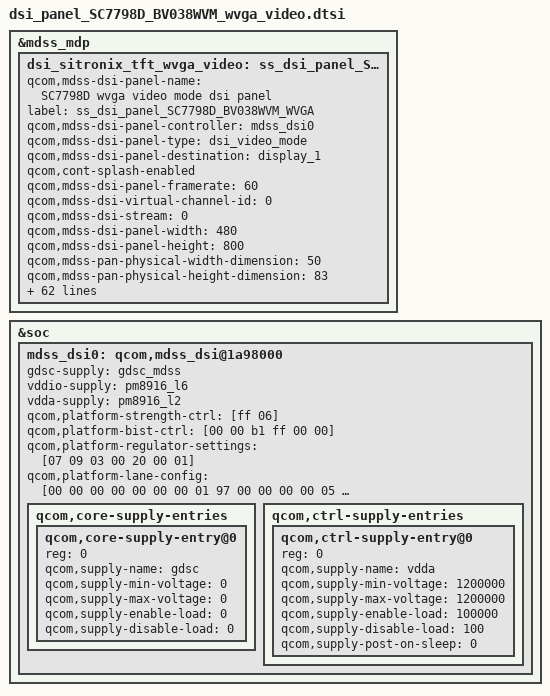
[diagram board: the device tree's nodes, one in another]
/* Copyright (c) 2013-14, Samsung Electronics Corporation. All rights reserved.
 *
 * This program is free software; you can redistribute it and/or modify
 * it under the terms of the GNU General Public License version 2 and
 * only version 2 as published by the Free Software Foundation.
 *
 * This program is distributed in the hope that it will be useful,
 * but WITHOUT ANY WARRANTY; without even the implied warranty of
 * MERCHANTABILITY or FITNESS FOR A PARTICULAR PURPOSE.  See the
 * GNU General Public License for more details.
 */

/*---------------------------------------------------------------------------
 * This file is autogenerated file using gcdb parser. Please do not edit it.
 * Update input XML file to add a new entry or update variable in this file
 * VERSION = "1.0"
 *---------------------------------------------------------------------------*/
&mdss_mdp {
	dsi_sitronix_tft_wvga_video: ss_dsi_panel_SC7798D_BV038WVM_WVGA/*qcom,mdss_dsi_sitronix_wvga_video*/ {
		qcom,mdss-dsi-panel-name = "SC7798D wvga video mode dsi panel";
		label = "ss_dsi_panel_SC7798D_BV038WVM_WVGA";
		qcom,mdss-dsi-panel-controller = <&mdss_dsi0>;
		qcom,mdss-dsi-panel-type = "dsi_video_mode";
		qcom,mdss-dsi-panel-destination = "display_1";
		qcom,cont-splash-enabled;
		qcom,mdss-dsi-panel-framerate = <60>;
		qcom,mdss-dsi-virtual-channel-id = <0>;
		qcom,mdss-dsi-stream = <0>;
		qcom,mdss-dsi-panel-width = <480>;
		qcom,mdss-dsi-panel-height = <800>;
		qcom,mdss-pan-physical-width-dimension = <50>; /* <Width> real size of panel in mm */
		qcom,mdss-pan-physical-height-dimension = <83>; /*<Height> real size of panel in mm */
		qcom,mdss-dsi-lp11-init;
		qcom,mdss-dsi-init-delay-us = <100>;
		qcom,mdss-dsi-h-front-porch = <90>;
		qcom,mdss-dsi-h-back-porch = <70>;
		qcom,mdss-dsi-h-pulse-width = <60>;
		qcom,mdss-dsi-h-sync-skew = <0>;
		qcom,mdss-dsi-v-back-porch = <12>;
		qcom,mdss-dsi-v-front-porch = <8>;
		qcom,mdss-dsi-v-pulse-width = <4>;
		qcom,mdss-dsi-h-left-border = <0>;
		qcom,mdss-dsi-h-right-border = <0>;
		qcom,mdss-dsi-v-top-border = <0>;
		qcom,mdss-dsi-v-bottom-border = <0>;
		qcom,mdss-dsi-bpp = <24>;
		qcom,mdss-dsi-color-order = <0>;
		qcom,mdss-dsi-underflow-color = <0xff>;
		qcom,mdss-dsi-border-color = <0>;
		qcom,mdss-dsi-dma-trigger = "trigger_sw";
		qcom,mdss-dsi-mdp-trigger = "none";
		qcom,mdss-dsi-bl-min-level = <1>;
		qcom,mdss-dsi-bl-max-level = <255>;
		qcom,mdss-dsi-bl-pmic-control-type = "bl_ctrl_dcs";
		qcom,mdss-dsi-lane-0-state;
		qcom,mdss-dsi-lane-1-state;
		qcom,mdss-dsi-bllp-eof-power-mode;
		qcom,mdss-dsi-bllp-power-mode;
		qcom,mdss-dsi-hbp-power-mode;
		qcom,mdss-dsi-traffic-mode = "burst_mode";
		qcom,mdss-dsi-force-clk-lane-hs;
		qcom,mdss-dsi-reset-sequence = <1 10>, <0 10>, <1 50>;
		qcom,mdss-dsi-h-sync-pulse = <0>;
		qcom,mdss-dsi-panel-timings = [6B 1A 10 00 3E 40 16 1C 15 03 04 00];
		qcom,mdss-dsi-t-clk-pre = <0x24>;
		qcom,mdss-dsi-t-clk-post = <0x04>;
		qcom,mdss-dsi-on-command = [
			39 01 00 00 00 00 04 B9 F1 08 00
			39 01 00 00 00 00 08 B1 42 14 16 A7 33 01 B7
			39 01 00 00 00 00 05 E3 05 05 01 02
			39 01 00 00 00 00 03 B8 06 22
			39 01 00 00 00 00 02 BC 67
			39 01 00 00 10 00 06 C0 73 50 00 08 70

			39 01 00 00 00 00 13 BA 31 00 44 25 91 0A 00 00 C2 34 00 00 04 02 4F B9 EE 40
			39 01 00 00 00 00 04 C6 00 00 F7
			39 01 00 00 00 00 02 CC 02
			39 01 00 00 00 00 02 B2 03
			39 01 00 00 00 00 02 B4 00
			39 01 00 00 00 00 09 B3 00 00 00 00 0A 0A 25 20

			39 01 00 00 00 00 34 E9 00 00 04 00 00 2F 2C 12 30
								00 48 08 2F 2C 47 00 60 00 00
								00 00 14 88 88 86 64 42 20 00
								29 00 00 00 87 75 53 31 11 39
								00 00 00 00 01 00 00 00 00 00
								00 00
			39 01 00 00 00 00 25 EA 00 00 91 13 35 57 73 18 00
								00 00 90 02 24 46 62 08 00 30
								01 00 FF 00 E8 00 00 00 00 00
								00 00 00 00 00 00 00

			39 01 00 00 00 00 23 E0 00 05 08 28 29 32 12 33 06
								09 09 11 12 10 12 31 38 00 05
								08 28 29 28 13 33 07 10 10 11
								12 10 12 31 38
			39 01 00 00 00 00 80 C1 01 00 08 10 18 20 28 30 38
								40 48 50 58 60 68 70 78 80 88
								90 98 A0 A8 B0 B8 C0 C8 D0 D8
								E0 E8 F0 F8 FF 00 00 00 00 00
								00 00 00 03 00 08 0F 17 1F 27
								2F 36 3E 46 4E 56 5D 65 6D 75
								7C 84 8C 94 9C A3 AB B3 BB C2
								CA D2 DA E2 E9 F1 F8 00 00 00
								00 00 00 00 00 03 00 08 10 18
								20 28 30 38 40 48 50 58 60 68
								70 78 80 88 90 98 A0 A8 B0 B8
								C0 C8 D0 D8 E0 E8 F0 F8 FF 00
								00 00 00 00 00 00 00 03

			39 01 00 00 00 00 02 C7 C0
			39 01 00 00 00 00 03 C8 11 01
			39 01 00 00 00 00 02 53 24
			05 01 00 00 78 00 02 11 00
			05 01 00 00 0A 00 02 29 00
		];

		qcom,mdss-dsi-on-command-state = "dsi_lp_mode";
		qcom,mdss-dsi-off-command-state = "dsi_hs_mode";
		qcom,mdss-dsi-off-command = [39 01 00 00 10 00 02 28 00
					39 01 00 00 46 00 02 10 00];
		samsung,display_on_tx_cmds_revA = [05 01 00 00 00 00 02 29 00];
		samsung,tft-common-support;
		samsung,mdss-dsi-bl-scale-low-level = <8>;
		samsung,mdss-dsi-bl-scale-dim-level = <8>;
		samsung,mdss-dsi-bl-scale-default-level = <89>;
		samsung,mdss-dsi-bl-scale-max-level = <188>;
		samsung,mdss-dsi-bl-pms-low-level = <7>;
		samsung,mdss-dsi-bl-pms-dim-level = <7>;
		samsung,mdss-dsi-bl-pms-default-level = <158>;
		samsung,mdss-dsi-bl-pms-max-level = <255>;
		samsung,panel-vendor = "BOE";
		samsung,tft_pwm_tx_cmds_revA=[
			39 01 00 00 00 00 02 51 FF/*First command should be PWM duty change command*/
		];
		samsung,cabc_on_tx_cmds_revA = [
			39 01 00 00 00 00 02 55 01
		];
		samsung,cabc_off_tx_cmds_revA = [
			39 01 00 00 00 00 02 55 00
		];
		/*
		* ************************************************************************************************************************
		* Scaled level to index mappings
		* ************************************************************************************************************************
		*/
		samsung,scaled_level_map_table_revA = <
		/*<idx>	  <from>  <till> <scaled_level> */
			0		0		7		8
			1		8		9		9
			2		10		12		10
			3		13		14		11
			4		15		17		12
			5		18		19		13
			6		20		22		14
			7		23		24		15
			8		25		27		16
			9		28		29		17
			10		30		32		18
			11		33		34		19
			12		35		37		20
			13		38		39		21
			14		40		42		22
			15		43		44		23
			16		45		47		24
			17		48		49		25
			18		50		52		26
			19		53		54		27
			20		55		57		28
			21		58		59		29
			22		60		62		30
			23		63		64		31
			24		65		67		32
			25		68		70		33
			26		71		72		34
			27		73		75		35
			28		76		77		36
			29		78		80		37
			30		81		82		38
			31		83		85		39
			32		86		87		40
			33		88		90		41
			34		91		92		42
			35		93		95		43
			36		96		97		45
			37		98		100		47
			38		101		102		49
			39		103		105		51
			40		106		107		53
			41		108		110		55
			42		111		112		57
			43		113		115		59
			44		116		117		61
			45		118		120		63
			46		121		122		65
			47		123		125		67
			48		126		127		69
			49		128		130		71
			50		131		133		73
			51		134		135		75
			52		136		138		77
			53		139		140		79
			54		141		143		81
			55		144		145		83
			56		146		148		85
			57		149		150		87
			58		151		153		89
			59		154		155		91
			60		156		158		93
			61		159		160		95
			62		161		163		98
			63		164		165		101
			64		166		168		104
			65		169		170		107
			66		171		173		110
			67		174		175		113
			68		176		178		116
			69		179		180		119
			70		181		183		122
			71		184		185		125
			72		186		188		128
			72		189		190		131
			74		191		193		134
			75		194		196		137
			76		197		198		140
			77		199		201		143
			78		202		203		146
			79		204		206		149
			80		207		208		152
			81		209		211		155
			82		212		213		158
			83		214		216		161
			84		217		218		164
			85		219		221		167
			86		222		223		170
			87		224		226		173
			88		227		228		176
			89		229		231		179
			90		232		233		182
			91		234		236		185
			92		237		238		188
			93		239		241		191
			94		242		243		195
			95		244		246		199
			96		247		248		202
			97		249		251		205
			98		252		253		208
			99		254		255		210
		>;
	};
};
&soc {
	mdss_dsi0: qcom,mdss_dsi@1a98000 {
		gdsc-supply = <&gdsc_mdss>;
		vddio-supply = <&pm8916_l6>;
		vdda-supply = <&pm8916_l2>;
		qcom,platform-strength-ctrl = [ff 06];
		qcom,platform-bist-ctrl = [00 00 b1 ff 00 00];
		qcom,platform-regulator-settings = [07 09 03 00 20 00 01];
		qcom,platform-lane-config = [00 00 00 00 00 00 00 01 97
			00 00 00 00 05 00 00 01 97
			00 00 00 00 0a 00 00 01 97
			00 00 00 00 0f 00 00 01 97
			00 c0 00 00 00 00 00 01 bb];
		qcom,core-supply-entries {
			#address-cells = <1>;
			#size-cells = <0>;

			qcom,core-supply-entry@0 {
				reg = <0>;
				qcom,supply-name = "gdsc";
				qcom,supply-min-voltage = <0>;
				qcom,supply-max-voltage = <0>;
				qcom,supply-enable-load = <0>;
				qcom,supply-disable-load = <0>;
			};
		};
		qcom,ctrl-supply-entries {
			#address-cells = <1>;
			#size-cells = <0>;

			qcom,ctrl-supply-entry@0 {
				reg = <0>;
				qcom,supply-name = "vdda";
				qcom,supply-min-voltage = <1200000>;
				qcom,supply-max-voltage = <1200000>;
				qcom,supply-enable-load = <100000>;
				qcom,supply-disable-load = <100>;
				qcom,supply-post-on-sleep = <0>;
			};
		};

	};
};

